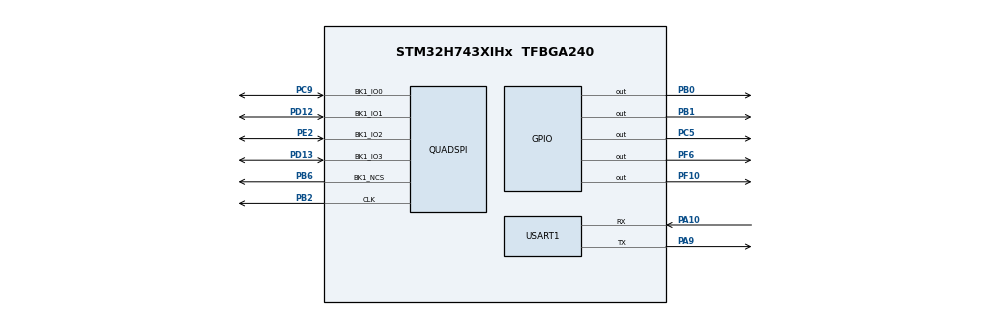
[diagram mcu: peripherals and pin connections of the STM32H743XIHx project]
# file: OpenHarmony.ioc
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CORTEX_M7.CPU_DCache=Enabled
CORTEX_M7.CPU_ICache=Enabled
CORTEX_M7.MPU_Control=__NULL
CORTEX_M7.default_mode_Activation=1
Mcu.Family=STM32H7
Mcu.Name=STM32H743XIHx
Mcu.Package=TFBGA240
NVIC.PriorityGroup=NVIC_PRIORITYGROUP_4
NVIC.QUADSPI_IRQn=true\:0\:0\:false\:false\:true\:true\:true\:true
NVIC.TIM1_UP_IRQn=true\:15\:0\:false\:false\:true\:false\:true\:true
NVIC.TimeBase=TIM1_UP_IRQn
NVIC.TimeBaseIP=TIM1
PA10.Mode=Asynchronous
PA10.Signal=USART1_RX
PA9.Mode=Asynchronous
PA9.Signal=USART1_TX
PB0.PinState=GPIO_PIN_SET
PB0.Signal=GPIO_Output
PB1.PinState=GPIO_PIN_SET
PB1.Signal=GPIO_Output
PB2.GPIO_Speed=GPIO_SPEED_FREQ_LOW
PB2.Mode=Single Bank 1
PB2.Signal=QUADSPI_CLK
PB6.GPIO_Speed=GPIO_SPEED_FREQ_LOW
PB6.Mode=Single Bank 1
PB6.Signal=QUADSPI_BK1_NCS
PC5.PinState=GPIO_PIN_SET
PC5.Signal=GPIO_Output
PC9.GPIO_PuPd=GPIO_NOPULL
PC9.GPIO_Speed=GPIO_SPEED_FREQ_LOW
PC9.Mode=Single Bank 1
PC9.Signal=QUADSPI_BK1_IO0
PD12.GPIO_Speed=GPIO_SPEED_FREQ_LOW
PD12.Mode=Single Bank 1
PD12.Signal=QUADSPI_BK1_IO1
PD13.GPIO_Speed=GPIO_SPEED_FREQ_LOW
PD13.Mode=Single Bank 1
PD13.Signal=QUADSPI_BK1_IO3
PE2.GPIO_Speed=GPIO_SPEED_FREQ_LOW
PE2.Mode=Single Bank 1
PE2.Signal=QUADSPI_BK1_IO2
PE7.Signal=QUADSPI_BK2_IO0
PE8.Signal=QUADSPI_BK2_IO1
PF10.Signal=GPIO_Output
PF6.Signal=GPIO_Output
PH0-OSC_IN\ (PH0).Mode=HSE-External-Oscillator
PH0-OSC_IN\ (PH0).Signal=RCC_OSC_IN
PH1-OSC_OUT\ (PH1).Mode=HSE-External-Oscillator
PH1-OSC_OUT\ (PH1).Signal=RCC_OSC_OUT
ProjectManager.HeapSize=0x200
ProjectManager.StackSize=0x400
ProjectManager.TargetToolchain=CMake
QUADSPI.ChipSelectHighTime=QSPI_CS_HIGH_TIME_1_CYCLE
QUADSPI.ClockMode=QSPI_CLOCK_MODE_0
QUADSPI.ClockPrescaler=11
QUADSPI.FifoThreshold=32
QUADSPI.FlashSize=31
QUADSPI.SampleShifting=QSPI_SAMPLE_SHIFTING_NONE
RCC.ADCFreq_Value=50390625
RCC.APB1Freq_Value=120000000
RCC.APB2Freq_Value=120000000
RCC.APB3Freq_Value=120000000
RCC.APB4Freq_Value=120000000
RCC.CortexFreq_Value=480000000
RCC.D1PPRE=RCC_APB3_DIV2
RCC.D2PPRE1=RCC_APB1_DIV2
RCC.D2PPRE2=RCC_APB2_DIV2
RCC.D3PPRE=RCC_APB4_DIV2
RCC.DIVM1=5
RCC.DIVN1=192
RCC.HCLKFreq_Value=240000000
RCC.HPRE=RCC_HCLK_DIV2
RCC.PLL2FRACN=0
RCC.PLL3FRACN=0
RCC.PLLFRACN=0
RCC.PLLSourceVirtual=RCC_PLLSOURCE_HSE
RCC.SYSCLKFreq_VALUE=480000000
RCC.SYSCLKSource=RCC_SYSCLKSOURCE_PLLCLK
RCC.USBCLockSelection=RCC_USBCLKSOURCE_HSI48
RCC.USBFreq_Value=48000000
STMicroelectronics.X-CUBE-TOUCHGFX.4.24.1.tgfx_hardware_accelerator=dma_custom
STMicroelectronics.X-CUBE-TOUCHGFX.4.24.1.tgfx_oswrapper=CMSIS V2
STMicroelectronics.X-CUBE-TOUCHGFX.4.24.1.tgfx_pixel_format=RGB888\:24
STMicroelectronics.X-CUBE-TOUCHGFX.4.24.1_IsPackSelfContextualization=true
USART1.VirtualMode-Asynchronous=VM_ASYNC
VP_CRC_VS_CRC.Mode=CRC_Activate
VP_MEMORYMAP_VS_MEMORYMAP.Mode=CurAppReg
VP_SYS_VS_tim1.Mode=TIM1
board=custom

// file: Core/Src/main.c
/* USER CODE BEGIN Header */
/**
  ******************************************************************************
  * @file           : main.c
  * @brief          : Main program body
  ******************************************************************************
  * @attention
  *
  * Copyright (c) 2024 STMicroelectronics.
  * All rights reserved.
  *
  * This software is licensed under terms that can be found in the LICENSE file
  * in the root directory of this software component.
  * If no LICENSE file comes with this software, it is provided AS-IS.
  *
  ******************************************************************************
  */
/* USER CODE END Header */
#include "main.h"
#include "crc.h"
#include "memorymap.h"
#include "quadspi.h"
#include "usart.h"
#include "gpio.h"

/* USER CODE BEGIN Includes */
#include <stdio.h>
#include "User.h"
/* USER CODE END Includes */

void SystemClock_Config(void);

/* USER CODE BEGIN 0 */
int _write(int fd, char *ptr, int len) {
    return HAL_UART_Transmit(&huart1, (uint8_t *) ptr, len, 0xFFFF);
}
/* USER CODE END 0 */

int main(void)
{

  /* Enable the CPU Cache */

  /* Enable I-Cache---------------------------------------------------------*/
  SCB_EnableICache();

  /* Enable D-Cache---------------------------------------------------------*/
  SCB_EnableDCache();

  /* MCU Configuration--------------------------------------------------------*/

  /* Reset of all peripherals, Initializes the Flash interface and the Systick. */
  HAL_Init();

  /* Configure the system clock */
  SystemClock_Config();

  /* Initialize all configured peripherals */
  MX_GPIO_Init();
  MX_CRC_Init();
  MX_QUADSPI_Init();
  MX_USART1_UART_Init();
  /* USER CODE BEGIN 2 */

    setup();

  /* USER CODE END 2 */

  /* Infinite loop */
  /* USER CODE BEGIN WHILE */
    while (1) {
        loop();
    /* USER CODE END WHILE */

    }
}

void SystemClock_Config(void)
{
  RCC_OscInitTypeDef RCC_OscInitStruct = {0};
  RCC_ClkInitTypeDef RCC_ClkInitStruct = {0};

  /** Supply configuration update enable
  */
  HAL_PWREx_ConfigSupply(PWR_LDO_SUPPLY);

  /** Configure the main internal regulator output voltage
  */
  __HAL_PWR_VOLTAGESCALING_CONFIG(PWR_REGULATOR_VOLTAGE_SCALE0);

  while(!__HAL_PWR_GET_FLAG(PWR_FLAG_VOSRDY)) {}

  /** Initializes the RCC Oscillators according to the specified parameters
  * in the RCC_OscInitTypeDef structure.
  */
  RCC_OscInitStruct.OscillatorType = RCC_OSCILLATORTYPE_HSE;
  RCC_OscInitStruct.HSEState = RCC_HSE_ON;
  RCC_OscInitStruct.PLL.PLLState = RCC_PLL_ON;
  RCC_OscInitStruct.PLL.PLLSource = RCC_PLLSOURCE_HSE;
  RCC_OscInitStruct.PLL.PLLM = 5;
  RCC_OscInitStruct.PLL.PLLN = 192;
  RCC_OscInitStruct.PLL.PLLP = 2;
  RCC_OscInitStruct.PLL.PLLQ = 2;
  RCC_OscInitStruct.PLL.PLLR = 2;
  RCC_OscInitStruct.PLL.PLLRGE = RCC_PLL1VCIRANGE_2;
  RCC_OscInitStruct.PLL.PLLVCOSEL = RCC_PLL1VCOWIDE;
  RCC_OscInitStruct.PLL.PLLFRACN = 0;
  if (HAL_RCC_OscConfig(&RCC_OscInitStruct) != HAL_OK)
  {
    Error_Handler();
  }

  /** Initializes the CPU, AHB and APB buses clocks
  */
  RCC_ClkInitStruct.ClockType = RCC_CLOCKTYPE_HCLK|RCC_CLOCKTYPE_SYSCLK
                              |RCC_CLOCKTYPE_PCLK1|RCC_CLOCKTYPE_PCLK2
                              |RCC_CLOCKTYPE_D3PCLK1|RCC_CLOCKTYPE_D1PCLK1;
  RCC_ClkInitStruct.SYSCLKSource = RCC_SYSCLKSOURCE_PLLCLK;
  RCC_ClkInitStruct.SYSCLKDivider = RCC_SYSCLK_DIV1;
  RCC_ClkInitStruct.AHBCLKDivider = RCC_HCLK_DIV2;
  RCC_ClkInitStruct.APB3CLKDivider = RCC_APB3_DIV2;
  RCC_ClkInitStruct.APB1CLKDivider = RCC_APB1_DIV2;
  RCC_ClkInitStruct.APB2CLKDivider = RCC_APB2_DIV2;
  RCC_ClkInitStruct.APB4CLKDivider = RCC_APB4_DIV2;

  if (HAL_RCC_ClockConfig(&RCC_ClkInitStruct, FLASH_LATENCY_4) != HAL_OK)
  {
    Error_Handler();
  }
}

void HAL_TIM_PeriodElapsedCallback(TIM_HandleTypeDef *htim)
{
  if (htim->Instance == TIM1) {
    HAL_IncTick();
  }
}

void Error_Handler(void)
{
    __disable_irq();
    while (1) {
    }
}
